# MCXN947_cm33_core0 register map
Vendor: nxp.com; File version: 1.0
CPU: CM33 r2p0, little endian, MPU, FPU, VTOR, 3 interrupt priority bits
Registers are 32-bit, read-write, reset 0x0 unless marked. A register's access mark holds for its fields unless they carry their own. Offsets are from the block's base; [hi:lo] are bit positions; lines under a group give offsets from that group; {n}, {i} and the like mark numbered series; 'fields as' and 'values as' point back to an identical list.

## BSP32_0 — CoolFlux BSP32
Base 0x40032000
0x00 offset_pmem — Offset address register for program memory
  [5:0] val
0x04 offset_xmem — Offset address register for X-data memory
  [7:0] val
0x08 offset_ymem — Offset address register for Y-data memory
  [7:0] val
0x0C offset_mailbox — Offset address register for mailbox peripheral
  [23:0] val
0x10 interrupts_external — External interrupt register
  [31:0] val
0x14 interrupts_status write-1-clears — Interrupt status register
  [0] val write-1-clears
0x18 cf_gating_override — CoolFlux BSP32 gating override
  [0] val
0x1C ivt_offset — CoolFlux BSP32 IVT offset register
  [23:0] val
0x20 sleep_mode ro — CoolFlux BSP32 sleep mode register
  [0] val
0x24 ivt0 reset 0x8 — CoolFlux BSP32 IVT register 0 content
  [23:0] val
0x28 ivt1 reset 0x9 — CoolFlux BSP32 IVT register 1 content
  [23:0] val
0x2C ivt2 reset 0xA — CoolFlux BSP32 IVT register 2 content
  [23:0] val
0x30 ivt3 reset 0xB — CoolFlux BSP32 IVT register 3 content
  [23:0] val
0x34 ivt_disable — CoolFlux BSP32 IVT disable register
  [0] val

## SMARTDMA0 — SmartDMA
Base 0x40033000
0x20 BOOTADR — Boot Address
  [31:2] ADDR — 32-bit boot address, the boot address should be 4-byte aligned.
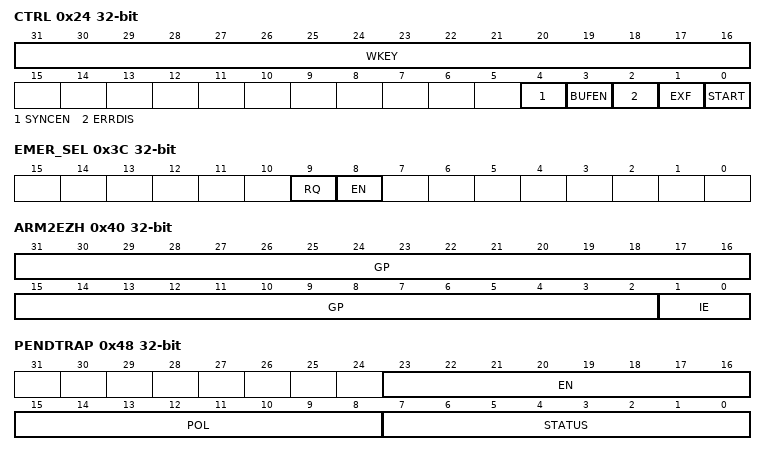
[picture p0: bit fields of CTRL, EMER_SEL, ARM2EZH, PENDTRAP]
0x24 CTRL — Control
  [31:16] WKEY — Write Key
  [4] SYNCEN — Sync Enable
  [3] BUFEN — Buffer Enable
  [2] ERRDIS — Error Disable
  [1] EXF — External Flag
  [0] START — Start Bit Ignition
0x28 PC ro — Program Counter
0x2C SP ro — Stack Pointer
0x30 BREAK_ADDR — Breakpoint Address
  [31:2] ADDR — 32-bit address to swap to EZHB_BREAK_VECT location
0x34 BREAK_VECT — Breakpoint Vector
  [31:2] VEC — Vector address of user debug routine.
0x38 EMER_VECT — Emergency Vector
  [31:2] VEC — Vector address of emergency code routine
0x3C EMER_SEL — Emergency Select
  [9] RQ — Software emergency request
  [8] EN — Emergency code routine
0x40 ARM2EZH — ARM to EZH Interrupt Control
  [31:2] GP — General purpose register bits
  [1:0] IE — Interrupt Enable
0x44 EZH2ARM — EZH to ARM Trigger
  [31:0] GP — General purpose register bits Writing to EZH2ARM triggers the ARM interrupt when ARM2EZH [1:0] == 2h
0x48 PENDTRAP — Pending Trap Control
  [23:16] EN — Enable Pending Trap
  [15:8] POL — Polarity
  [7:0] STATUS — Status Flag or Pending Trap Request

## PLU0 — Programmable Logic Unit (PLU)
Base 0x40034000
{0x0+0x20*i} LUT[{i}] (i=0..25) group
  {0x0+4j} LUT_INP_MUX{j} (j=0..4) reset 0x3F — Input select register for LUTn (0 to 25), Inputx (5 inputs)
    [5:0] LUTn_INPx — Selects the input source to be connected to LUTn_INPx
      {v}=plu_inputs{v} (PLU primary inputs {v}) (v=0..5); {v}=lut_outputs{v-6} (Output of LUT{v-6}) (v=6..31); {v}=state{v-32} (v=32..35)
{0x800+4i} LUT_TRUTH[{i}] (i=0..25) — PLU LUT truth table
  [31:0] LUT_TRUTH — LUT truth table
0x900 OUTPUTS ro — PLU outputs
  [7:0] OUTPUT_STATE
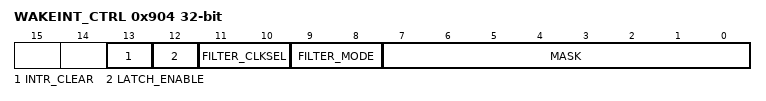
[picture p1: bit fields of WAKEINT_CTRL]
0x904 WAKEINT_CTRL — Wakeup interrupt control
  [13] INTR_CLEAR write-1-clears — Write to clear wakeint_latched
  [12] LATCH_ENABLE — Latch the interrupt
  [11:10] FILTER_CLKSEL — Filter clock select
    0=FRO1MHZ (Selects the 1 MHz low-power oscillator as the filter clock.); 1=FRO12MHZ (Selects the 12 MHz FRO as the filter clock.)
  [9:8] FILTER_MODE
    0=BYPASS (Bypass mode); 1=FILTER1CLK (Filter 1 clock period); 2=FILTER2CLK (Filter 2 clock period); 3=FILTER3CLK (Filter 3 clock period)
  [7:0] MASK — Interrupt mask
{0xC00+4i} OUTPUT_MUX[{i}] (i=0..7) reset 0x1F — PLU output multiplexer
  [4:0] OUTPUT — Selects the source to be connected to PLU output n.
    {v}=plu_output{v} (LUT output {v}) (v=0..25); {v}=state{v-26} (v=26..29)

## PORT5 — PORT
Base 0x40042000
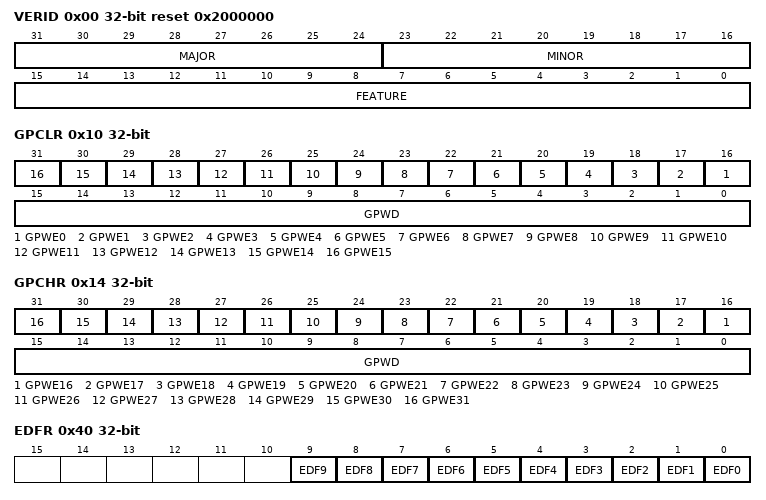
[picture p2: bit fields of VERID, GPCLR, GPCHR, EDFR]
0x00 VERID ro reset 0x2000000 — Version ID
  [31:24] MAJOR — Major Version Number
  [23:16] MINOR — Minor Version Number
  [15:0] FEATURE — Feature Specification Number
    0=Basic implementation
0x10 GPCLR — Global Pin Control Low
  [n+16] GPWE{n} (n=0..15) — Global Pin Write Enable
    0=gpwe0 (Not updated); 1=gpwe1 (Updated)
  [15:0] GPWD — Global Pin Write Data
0x14 GPCHR — Global Pin Control High
  [n] GPWE{n} (n=16..31) — Global Pin Write Enable
    0=gpwe0 (Not updated); 1=gpwe1 (Updated)
  [15:0] GPWD — Global Pin Write Data
0x20 CONFIG — Configuration
  [0] RANGE — Port Voltage Range
    0=1.71 V-3.6 V; 1=2.70 V-3.6 V
0x40 EDFR ro reset not defined — EFT Detect Flag
  [all] fields
    0=edie0 (No EFT event detected); 1=edie1 (High or/and low EFT event detected)
  [n] EDF{n} (n=0..9) — EFT Detect Flag
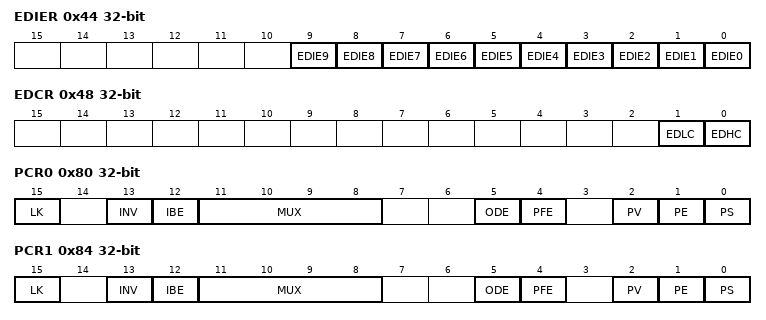
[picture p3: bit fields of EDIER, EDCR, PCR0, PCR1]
0x44 EDIER — EFT Detect Interrupt Enable
  [all] fields
    0=edie0 (Interrupt not generated upon detection of the EFT event); 1=edie1 (Interrupt generated upon detection of the EFT event)
  [n] EDIE{n} (n=0..9) — EFT Detect Interrupt Enable
0x48 EDCR — EFT Detect Clear
  [1] EDLC — EFT Detect Low Clear
    0=Does not clear; 1=Clears
  [0] EDHC — EFT Detect High Clear
    0=Does not clear; 1=Clears
0x80 PCR0 — Pin Control 0
  [15] LK — Lock Register
    0=Does not lock; 1=Locks
  [13] INV — Invert Input
    0=Does not invert; 1=Inverts
  [12] IBE — Input Buffer Enable
    0=Disables; 1=Enables
  [11:8] MUX — Pin Multiplex Control
    0=Alternative 0 (GPIO); 1=Alternative 1 (chip-specific); 2=Alternative 2 (chip-specific); 3=Alternative 3 (chip-specific)
  [5] ODE — Open Drain Enable
    0=Disables; 1=Enables
  [4] PFE — Passive Filter Enable
    0=Disables; 1=Enables
  [2] PV — Pull Value
    0=Low; 1=High
  [1] PE — Pull Enable
    0=Disables; 1=Enables
  [0] PS — Pull Select
    0=Enables internal pulldown resistor; 1=Enables internal pullup resistor
0x84 PCR1 — Pin Control 1
  fields as PCR0
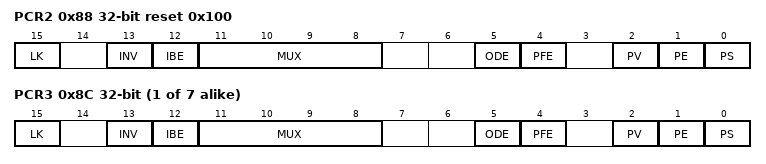
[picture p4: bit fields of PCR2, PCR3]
0x88 PCR2 reset 0x100 — Pin Control 2
  fields as PCR0
{0x80+4i} PCR{i} (i=3..9) — Pin Control {i}
  fields as PCR0
